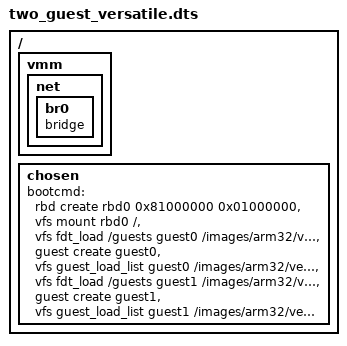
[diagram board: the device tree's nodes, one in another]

/dts-v1/;

/include/ "3dstack.dtsi"

/ {
	vmm {
		net {
			br0 {
				device_type = "netswitch";
				compatible = "bridge";
			};
		};
	};

	chosen {
		bootcmd = /* Create rbd0 device */
			  "rbd create rbd0 0x81000000 0x01000000",

			  /* Mount rbd0 device */
			  "vfs mount rbd0 /",

			  /* Load guest0 device tree from file */
			  "vfs fdt_load /guests guest0 /images/arm32/versatilepb.dtb mem0,physical_size,physsize,0x02000000 net0,switch,string,br0",

			  /* Create guest0 */
			  "guest create guest0",

			  /* Load guest0 images */
			  "vfs guest_load_list guest0 /images/arm32/versatilepb/nor_flash.list",

			  /* Load guest1 device tree from file */
			  "vfs fdt_load /guests guest1 /images/arm32/versatilepb.dtb mem0,physical_size,physsize,0x02000000 net0,switch,string,br0",

			  /* Create guest1 */
			  "guest create guest1",

			  /* Load guest1 images */
			  "vfs guest_load_list guest1 /images/arm32/versatilepb/nor_flash.list";
	};
};
